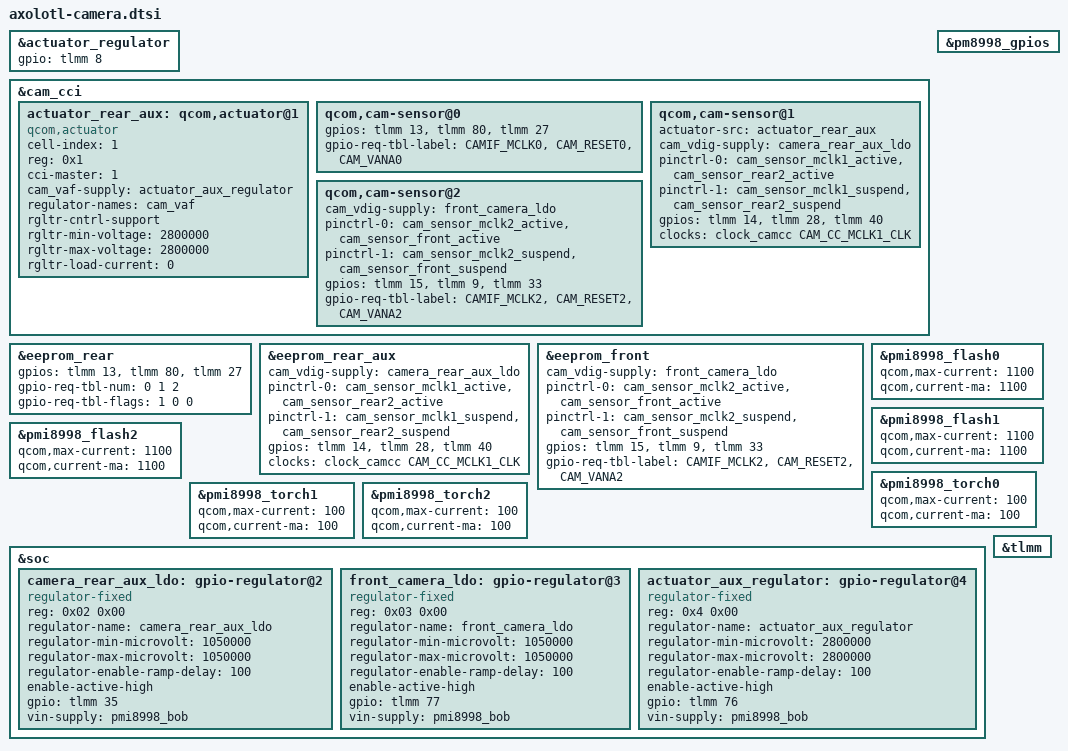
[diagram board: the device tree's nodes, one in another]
// SPDX-License-Identifier: GPL-2.0-only
/*
 * Copyright (c) 2020-2023, SHIFT GmbH. All rights reserved.
 */

&actuator_regulator {
	gpio = <&tlmm 8 0>;
};

&cam_cci {
	/delete-node/ actuator_front;
	/delete-node/ ois_rear;

	actuator_rear_aux: qcom,actuator@1 {
		cell-index = <1>;
		reg = <0x1>;
		compatible = "qcom,actuator";
		cci-master = <1>;
		cam_vaf-supply = <&actuator_aux_regulator>;
		regulator-names = "cam_vaf";
		rgltr-cntrl-support;
		rgltr-min-voltage = <2800000>;
		rgltr-max-voltage = <2800000>;
		rgltr-load-current = <0>;
	};

	qcom,cam-sensor@0 {
		/delete-property/ ois-src;

		gpios = <&tlmm 13 0>,
			<&tlmm 80 0>,
			<&tlmm 27 0>;

		gpio-req-tbl-label = "CAMIF_MCLK0",
					"CAM_RESET0",
					"CAM_VANA0";
	};

	qcom,cam-sensor@1 {
		actuator-src = <&actuator_rear_aux>;
		cam_vdig-supply = <&camera_rear_aux_ldo>;

		pinctrl-0 = <&cam_sensor_mclk1_active
				&cam_sensor_rear2_active>;
		pinctrl-1 = <&cam_sensor_mclk1_suspend
				&cam_sensor_rear2_suspend>;
		gpios = <&tlmm 14 0>,
			<&tlmm 28 0>,
			<&tlmm 40 0>;

		clocks = <&clock_camcc CAM_CC_MCLK1_CLK>;
	};

	qcom,cam-sensor@2 {
		/delete-property/ actuator-src;
		/delete-property/ led-flash-src;
		cam_vdig-supply = <&front_camera_ldo>;

		pinctrl-0 = <&cam_sensor_mclk2_active
				 &cam_sensor_front_active>;
		pinctrl-1 = <&cam_sensor_mclk2_suspend
				 &cam_sensor_front_suspend>;
		gpios = <&tlmm 15 0>,
			<&tlmm 9 0>,
			<&tlmm 33 0>;

		gpio-req-tbl-label = "CAMIF_MCLK2",
					"CAM_RESET2",
					"CAM_VANA2";
	};
};

&eeprom_rear {
	gpios = <&tlmm 13 0>,
		<&tlmm 80 0>,
		<&tlmm 27 0>;

	/delete-property/ gpio-vaf;
	gpio-req-tbl-num = <0 1 2>;
	gpio-req-tbl-flags = <1 0 0>;
};

&eeprom_rear_aux {
	cam_vdig-supply = <&camera_rear_aux_ldo>;

	pinctrl-0 = <&cam_sensor_mclk1_active
			&cam_sensor_rear2_active>;
	pinctrl-1 = <&cam_sensor_mclk1_suspend
			&cam_sensor_rear2_suspend>;
	gpios = <&tlmm 14 0>,
		<&tlmm 28 0>,
		<&tlmm 40 0>;

	clocks = <&clock_camcc CAM_CC_MCLK1_CLK>;
};

&eeprom_front {
	cam_vdig-supply = <&front_camera_ldo>;

	pinctrl-0 = <&cam_sensor_mclk2_active
				&cam_sensor_front_active>;
	pinctrl-1 = <&cam_sensor_mclk2_suspend
				&cam_sensor_front_suspend>;
	gpios = <&tlmm 15 0>,
		<&tlmm 9 0>,
		<&tlmm 33 0>;

	gpio-req-tbl-label = "CAMIF_MCLK2",
				"CAM_RESET2",
				"CAM_VANA2";
};

&pm8998_gpios {
	/delete-node/ camera_dvdd_en;
	/delete-node/ camera_rear_avdd_en;
};

&pmi8998_flash0 {
	qcom,max-current = <1100>;
	qcom,current-ma = <1100>;
};

&pmi8998_flash1 {
	qcom,max-current = <1100>;
	qcom,current-ma = <1100>;
};

&pmi8998_flash2 {
	qcom,max-current = <1100>;
	qcom,current-ma = <1100>;
};

&pmi8998_torch0 {
	qcom,max-current = <100>;
	qcom,current-ma = <100>;
};

&pmi8998_torch1 {
	qcom,max-current = <100>;
	qcom,current-ma = <100>;
};

&pmi8998_torch2 {
	qcom,max-current = <100>;
	qcom,current-ma = <100>;
};

&soc {
	/delete-node/ camera_ldo;

	camera_rear_aux_ldo: gpio-regulator@2 {
		compatible = "regulator-fixed";
		reg = <0x02 0x00>;
		regulator-name = "camera_rear_aux_ldo";
		regulator-min-microvolt = <1050000>;
		regulator-max-microvolt = <1050000>;
		regulator-enable-ramp-delay = <100>;
		enable-active-high;
		gpio = <&tlmm 35 0>;
		vin-supply = <&pmi8998_bob>;
	};

	front_camera_ldo: gpio-regulator@3 {
		compatible = "regulator-fixed";
		reg = <0x03 0x00>;
		regulator-name = "front_camera_ldo";
		regulator-min-microvolt = <1050000>;
		regulator-max-microvolt = <1050000>;
		regulator-enable-ramp-delay = <100>;
		enable-active-high;
		gpio = <&tlmm 77 0>;
		vin-supply = <&pmi8998_bob>;
	};

	actuator_aux_regulator: gpio-regulator@4 {
		compatible = "regulator-fixed";
		reg = <0x4 0x00>;
		regulator-name = "actuator_aux_regulator";
		regulator-min-microvolt = <2800000>;
		regulator-max-microvolt = <2800000>;
		regulator-enable-ramp-delay = <100>;
		enable-active-high;
		gpio = <&tlmm 76 0>;
		vin-supply = <&pmi8998_bob>;
	};
};

&tlmm {
	/delete-node/ cam_sensor_rear_vana;
};
